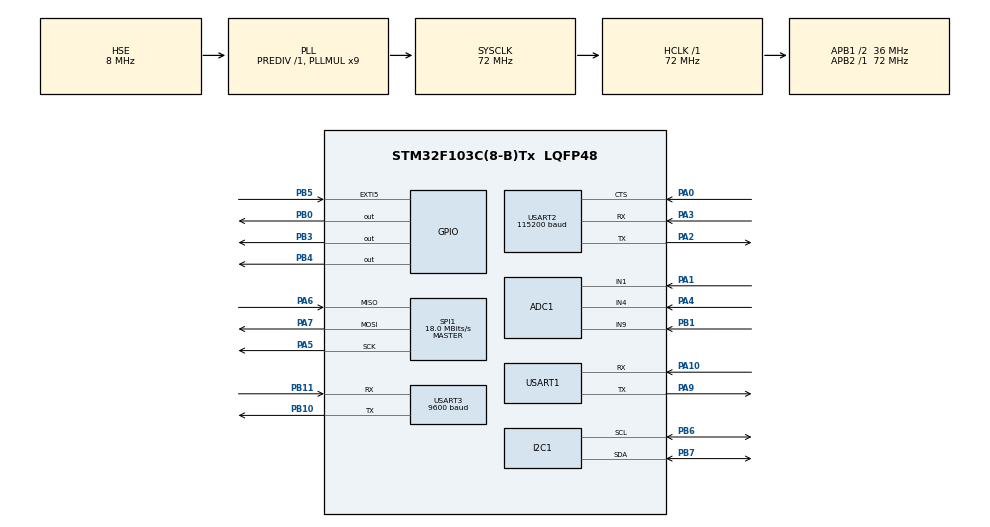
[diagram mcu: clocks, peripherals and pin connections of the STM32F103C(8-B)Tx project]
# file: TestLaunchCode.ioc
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ADC1.Channel-2\#ChannelRegularConversion=ADC_CHANNEL_9
ADC1.Channel-3\#ChannelRegularConversion=ADC_CHANNEL_1
ADC1.Channel-4\#ChannelRegularConversion=ADC_CHANNEL_4
ADC1.ContinuousConvMode=DISABLE
ADC1.DataAlign=ADC_DATAALIGN_RIGHT
ADC1.DiscontinuousConvMode=ENABLE
ADC1.NbrOfConversion=3
ADC1.NbrOfConversionFlag=1
ADC1.Rank-2\#ChannelRegularConversion=1
ADC1.Rank-3\#ChannelRegularConversion=2
ADC1.Rank-4\#ChannelRegularConversion=3
ADC1.SamplingTime-2\#ChannelRegularConversion=ADC_SAMPLETIME_1CYCLE_5
ADC1.SamplingTime-3\#ChannelRegularConversion=ADC_SAMPLETIME_1CYCLE_5
ADC1.SamplingTime-4\#ChannelRegularConversion=ADC_SAMPLETIME_1CYCLE_5
ADC1.master=1
FATFS._MAX_SS=4096
FATFS._USE_LFN=1
I2C1.I2C_Mode=I2C_Standard
Mcu.Family=STM32F1
Mcu.Name=STM32F103C(8-B)Tx
Mcu.Package=LQFP48
NVIC.PriorityGroup=NVIC_PRIORITYGROUP_3
NVIC.USART1_IRQn=true\:1\:1\:true\:false\:true\:true\:true
NVIC.USART2_IRQn=true\:1\:1\:true\:false\:true\:true\:true
NVIC.USART3_IRQn=true\:0\:0\:true\:false\:true\:true\:true
PA0-WKUP.Mode=CTS_Only
PA0-WKUP.Signal=USART2_CTS
PA1.Signal=ADCx_IN1
PA10.Mode=Asynchronous
PA10.Signal=USART1_RX
PA13.Mode=Serial_Wire
PA13.Signal=SYS_JTMS-SWDIO
PA14.Mode=Serial_Wire
PA14.Signal=SYS_JTCK-SWCLK
PA2.Mode=Asynchronous
PA2.Signal=USART2_TX
PA3.Mode=Asynchronous
PA3.Signal=USART2_RX
PA4.Signal=ADCx_IN4
PA5.Mode=Full_Duplex_Master
PA5.Signal=SPI1_SCK
PA6.Mode=Full_Duplex_Master
PA6.Signal=SPI1_MISO
PA7.Mode=Full_Duplex_Master
PA7.Signal=SPI1_MOSI
PA9.Mode=Asynchronous
PA9.Signal=USART1_TX
PB0.Signal=GPIO_Output
PB1.Signal=ADCx_IN9
PB10.Mode=Asynchronous
PB10.Signal=USART3_TX
PB11.Mode=Asynchronous
PB11.Signal=USART3_RX
PB3.Signal=GPIO_Output
PB4.Signal=GPIO_Output
PB5.Signal=GPXTI5
PB6.Mode=I2C
PB6.Signal=I2C1_SCL
PB7.Mode=I2C
PB7.Signal=I2C1_SDA
PB8.Signal=CAN_RX
PC14-OSC32_IN.Mode=LSE-External-Oscillator
PC14-OSC32_IN.Signal=RCC_OSC32_IN
PC15-OSC32_OUT.Mode=LSE-External-Oscillator
PC15-OSC32_OUT.Signal=RCC_OSC32_OUT
PD0-OSC_IN.Mode=HSE-External-Oscillator
PD0-OSC_IN.Signal=RCC_OSC_IN
PD1-OSC_OUT.Mode=HSE-External-Oscillator
PD1-OSC_OUT.Signal=RCC_OSC_OUT
ProjectManager.HeapSize=0x200
ProjectManager.StackSize=0x400
ProjectManager.TargetToolchain=STM32CubeIDE
RCC.ADCPresc=RCC_ADCPCLK2_DIV6
RCC.AHBFreq_Value=72000000
RCC.APB1CLKDivider=RCC_HCLK_DIV2
RCC.APB1Freq_Value=36000000
RCC.APB1TimFreq_Value=72000000
RCC.APB2Freq_Value=72000000
RCC.APB2TimFreq_Value=72000000
RCC.HCLKFreq_Value=72000000
RCC.PLLMUL=RCC_PLL_MUL9
RCC.PLLSourceVirtual=RCC_PLLSOURCE_HSE
RCC.SYSCLKFreq_VALUE=72000000
RCC.SYSCLKSource=RCC_SYSCLKSOURCE_PLLCLK
RCC.USBFreq_Value=72000000
SH.ADCx_IN1.0=ADC1_IN1,IN1
SH.ADCx_IN4.0=ADC1_IN4,IN4
SH.ADCx_IN9.0=ADC1_IN9,IN9
SPI1.BaudRatePrescaler=SPI_BAUDRATEPRESCALER_4
SPI1.CalculateBaudRate=18.0 MBits/s
SPI1.Direction=SPI_DIRECTION_2LINES
SPI1.Mode=SPI_MODE_MASTER
SPI1.VirtualType=VM_MASTER
USART1.VirtualMode=VM_ASYNC
USART2.BaudRate=115200
USART2.VirtualMode=VM_ASYNC
USART3.BaudRate=9600
USART3.VirtualMode=VM_ASYNC
VP_FATFS_VS_Generic.Mode=User_defined
board=custom

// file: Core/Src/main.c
/* USER CODE BEGIN Header */
/**
  ******************************************************************************
  * @file           : main.c
  * @brief          : Main program body
  ******************************************************************************
  * @attention
  *
  * <h2><center>&copy; Copyright (c) 2020 STMicroelectronics.
  * All rights reserved.</center></h2>
  *
  * This software component is licensed by ST under BSD 3-Clause license,
  * the "License"; You may not use this file except in compliance with the
  * License. You may obtain a copy of the License at:
  *                        opensource.org/licenses/BSD-3-Clause
  *
  ******************************************************************************
  */
/* USER CODE END Header */

#include "main.h"
#include "fatfs.h"

/* USER CODE BEGIN Includes */
#include <stdio.h>
#include <string.h>
/* USER CODE END Includes */

ADC_HandleTypeDef hadc1;

I2C_HandleTypeDef hi2c1;

SPI_HandleTypeDef hspi1;

UART_HandleTypeDef huart1;
UART_HandleTypeDef huart2;
UART_HandleTypeDef huart3;

void SystemClock_Config(void);
static void MX_GPIO_Init(void);
static void MX_ADC1_Init(void);
static void MX_I2C1_Init(void);
static void MX_SPI1_Init(void);
static void MX_USART2_UART_Init(void);
static void MX_USART1_UART_Init(void);
static void MX_USART3_UART_Init(void);

/* USER CODE BEGIN 0 */
int maincpp(void);
/* USER CODE END 0 */

int main(void)
{

  /* MCU Configuration--------------------------------------------------------*/

  /* Reset of all peripherals, Initializes the Flash interface and the Systick. */
  HAL_Init();

  /* Configure the system clock */
  SystemClock_Config();

  /* Initialize all configured peripherals */
  MX_GPIO_Init();
  MX_ADC1_Init();
  MX_I2C1_Init();
  MX_SPI1_Init();
  MX_USART2_UART_Init();
  MX_USART1_UART_Init();
  MX_USART3_UART_Init();
  MX_FATFS_Init();
  /* USER CODE BEGIN 2 */
  maincpp();
  /* USER CODE END 2 */

  /* Infinite loop */
  /* USER CODE BEGIN WHILE */
  while (1)
  {
  	// This code is never reached
    /* USER CODE END WHILE */

    /* USER CODE BEGIN 3 */
  	// This code is never reached
  }
  /* USER CODE END 3 */
}

void SystemClock_Config(void)
{
  RCC_OscInitTypeDef RCC_OscInitStruct = {0};
  RCC_ClkInitTypeDef RCC_ClkInitStruct = {0};
  RCC_PeriphCLKInitTypeDef PeriphClkInit = {0};

  /** Initializes the CPU, AHB and APB busses clocks
  */
  RCC_OscInitStruct.OscillatorType = RCC_OSCILLATORTYPE_HSE;
  RCC_OscInitStruct.HSEState = RCC_HSE_ON;
  RCC_OscInitStruct.HSEPredivValue = RCC_HSE_PREDIV_DIV1;
  RCC_OscInitStruct.HSIState = RCC_HSI_ON;
  RCC_OscInitStruct.PLL.PLLState = RCC_PLL_ON;
  RCC_OscInitStruct.PLL.PLLSource = RCC_PLLSOURCE_HSE;
  RCC_OscInitStruct.PLL.PLLMUL = RCC_PLL_MUL9;
  if (HAL_RCC_OscConfig(&RCC_OscInitStruct) != HAL_OK)
  {
    Error_Handler();
  }
  /** Initializes the CPU, AHB and APB busses clocks
  */
  RCC_ClkInitStruct.ClockType = RCC_CLOCKTYPE_HCLK|RCC_CLOCKTYPE_SYSCLK
                              |RCC_CLOCKTYPE_PCLK1|RCC_CLOCKTYPE_PCLK2;
  RCC_ClkInitStruct.SYSCLKSource = RCC_SYSCLKSOURCE_PLLCLK;
  RCC_ClkInitStruct.AHBCLKDivider = RCC_SYSCLK_DIV1;
  RCC_ClkInitStruct.APB1CLKDivider = RCC_HCLK_DIV2;
  RCC_ClkInitStruct.APB2CLKDivider = RCC_HCLK_DIV1;

  if (HAL_RCC_ClockConfig(&RCC_ClkInitStruct, FLASH_LATENCY_2) != HAL_OK)
  {
    Error_Handler();
  }
  PeriphClkInit.PeriphClockSelection = RCC_PERIPHCLK_ADC;
  PeriphClkInit.AdcClockSelection = RCC_ADCPCLK2_DIV6;
  if (HAL_RCCEx_PeriphCLKConfig(&PeriphClkInit) != HAL_OK)
  {
    Error_Handler();
  }
}

static void MX_ADC1_Init(void)
{

  ADC_ChannelConfTypeDef sConfig = {0};

  /** Common config
  */
  hadc1.Instance = ADC1;
  hadc1.Init.ScanConvMode = ADC_SCAN_ENABLE;
  hadc1.Init.ContinuousConvMode = DISABLE;
  hadc1.Init.DiscontinuousConvMode = ENABLE;
  hadc1.Init.NbrOfDiscConversion = 1;
  hadc1.Init.ExternalTrigConv = ADC_SOFTWARE_START;
  hadc1.Init.DataAlign = ADC_DATAALIGN_RIGHT;
  hadc1.Init.NbrOfConversion = 3;
  if (HAL_ADC_Init(&hadc1) != HAL_OK)
  {
    Error_Handler();
  }
  /** Configure Regular Channel
  */
  sConfig.Channel = ADC_CHANNEL_9;
  sConfig.Rank = ADC_REGULAR_RANK_1;
  sConfig.SamplingTime = ADC_SAMPLETIME_1CYCLE_5;
  if (HAL_ADC_ConfigChannel(&hadc1, &sConfig) != HAL_OK)
  {
    Error_Handler();
  }
  /** Configure Regular Channel
  */
  sConfig.Channel = ADC_CHANNEL_1;
  sConfig.Rank = ADC_REGULAR_RANK_2;
  if (HAL_ADC_ConfigChannel(&hadc1, &sConfig) != HAL_OK)
  {
    Error_Handler();
  }
  /** Configure Regular Channel
  */
  sConfig.Channel = ADC_CHANNEL_4;
  sConfig.Rank = ADC_REGULAR_RANK_3;
  if (HAL_ADC_ConfigChannel(&hadc1, &sConfig) != HAL_OK)
  {
    Error_Handler();
  }

}

static void MX_I2C1_Init(void)
{

  hi2c1.Instance = I2C1;
  hi2c1.Init.ClockSpeed = 100000;
  hi2c1.Init.DutyCycle = I2C_DUTYCYCLE_2;
  hi2c1.Init.OwnAddress1 = 0;
  hi2c1.Init.AddressingMode = I2C_ADDRESSINGMODE_7BIT;
  hi2c1.Init.DualAddressMode = I2C_DUALADDRESS_DISABLE;
  hi2c1.Init.OwnAddress2 = 0;
  hi2c1.Init.GeneralCallMode = I2C_GENERALCALL_DISABLE;
  hi2c1.Init.NoStretchMode = I2C_NOSTRETCH_DISABLE;
  if (HAL_I2C_Init(&hi2c1) != HAL_OK)
  {
    Error_Handler();
  }

}

static void MX_SPI1_Init(void)
{

  /* SPI1 parameter configuration*/
  hspi1.Instance = SPI1;
  hspi1.Init.Mode = SPI_MODE_MASTER;
  hspi1.Init.Direction = SPI_DIRECTION_2LINES;
  hspi1.Init.DataSize = SPI_DATASIZE_8BIT;
  hspi1.Init.CLKPolarity = SPI_POLARITY_LOW;
  hspi1.Init.CLKPhase = SPI_PHASE_1EDGE;
  hspi1.Init.NSS = SPI_NSS_SOFT;
  hspi1.Init.BaudRatePrescaler = SPI_BAUDRATEPRESCALER_4;
  hspi1.Init.FirstBit = SPI_FIRSTBIT_MSB;
  hspi1.Init.TIMode = SPI_TIMODE_DISABLE;
  hspi1.Init.CRCCalculation = SPI_CRCCALCULATION_DISABLE;
  hspi1.Init.CRCPolynomial = 10;
  if (HAL_SPI_Init(&hspi1) != HAL_OK)
  {
    Error_Handler();
  }

}

static void MX_USART1_UART_Init(void)
{

  huart1.Instance = USART1;
  huart1.Init.BaudRate = 115200;
  huart1.Init.WordLength = UART_WORDLENGTH_8B;
  huart1.Init.StopBits = UART_STOPBITS_1;
  huart1.Init.Parity = UART_PARITY_NONE;
  huart1.Init.Mode = UART_MODE_TX_RX;
  huart1.Init.HwFlowCtl = UART_HWCONTROL_NONE;
  huart1.Init.OverSampling = UART_OVERSAMPLING_16;
  if (HAL_UART_Init(&huart1) != HAL_OK)
  {
    Error_Handler();
  }

}

static void MX_USART2_UART_Init(void)
{

  huart2.Instance = USART2;
  huart2.Init.BaudRate = 115200;
  huart2.Init.WordLength = UART_WORDLENGTH_8B;
  huart2.Init.StopBits = UART_STOPBITS_1;
  huart2.Init.Parity = UART_PARITY_NONE;
  huart2.Init.Mode = UART_MODE_TX_RX;
  huart2.Init.HwFlowCtl = UART_HWCONTROL_CTS;
  huart2.Init.OverSampling = UART_OVERSAMPLING_16;
  if (HAL_UART_Init(&huart2) != HAL_OK)
  {
    Error_Handler();
  }

}

static void MX_USART3_UART_Init(void)
{

  huart3.Instance = USART3;
  huart3.Init.BaudRate = 9600;
  huart3.Init.WordLength = UART_WORDLENGTH_8B;
  huart3.Init.StopBits = UART_STOPBITS_1;
  huart3.Init.Parity = UART_PARITY_NONE;
  huart3.Init.Mode = UART_MODE_TX_RX;
  huart3.Init.HwFlowCtl = UART_HWCONTROL_NONE;
  huart3.Init.OverSampling = UART_OVERSAMPLING_16;
  if (HAL_UART_Init(&huart3) != HAL_OK)
  {
    Error_Handler();
  }

}

static void MX_GPIO_Init(void)
{
  GPIO_InitTypeDef GPIO_InitStruct = {0};

  /* GPIO Ports Clock Enable */
  __HAL_RCC_GPIOC_CLK_ENABLE();
  __HAL_RCC_GPIOD_CLK_ENABLE();
  __HAL_RCC_GPIOA_CLK_ENABLE();
  __HAL_RCC_GPIOB_CLK_ENABLE();

  /*Configure GPIO pin Output Level */
  HAL_GPIO_WritePin(GPIOB, GPIO_PIN_0|GPIO_PIN_3|GPIO_PIN_4, GPIO_PIN_RESET);

  /*Configure GPIO pins : PB0 PB3 PB4 */
  GPIO_InitStruct.Pin = GPIO_PIN_0|GPIO_PIN_3|GPIO_PIN_4;
  GPIO_InitStruct.Mode = GPIO_MODE_OUTPUT_PP;
  GPIO_InitStruct.Pull = GPIO_NOPULL;
  GPIO_InitStruct.Speed = GPIO_SPEED_FREQ_LOW;
  HAL_GPIO_Init(GPIOB, &GPIO_InitStruct);

  /*Configure GPIO pin : PB5 */
  GPIO_InitStruct.Pin = GPIO_PIN_5;
  GPIO_InitStruct.Mode = GPIO_MODE_IT_RISING;
  GPIO_InitStruct.Pull = GPIO_NOPULL;
  HAL_GPIO_Init(GPIOB, &GPIO_InitStruct);

  /*Configure GPIO pin : PB8 */
  GPIO_InitStruct.Pin = GPIO_PIN_8;
  GPIO_InitStruct.Mode = GPIO_MODE_INPUT;
  GPIO_InitStruct.Pull = GPIO_NOPULL;
  HAL_GPIO_Init(GPIOB, &GPIO_InitStruct);

  /*Configure peripheral I/O remapping */
  __HAL_AFIO_REMAP_CAN1_2();

}

void Error_Handler(void)
{
}

/************************ (C) COPYRIGHT STMicroelectronics *****END OF FILE****/
